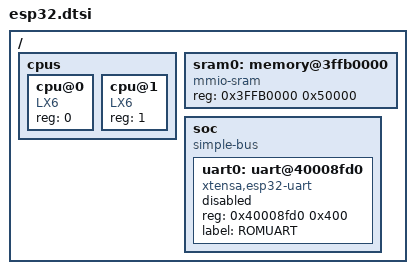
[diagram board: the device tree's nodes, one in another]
/*
 * Copyright (c) 2019 Intel Corporation.
 *
 * SPDX-License-Identifier: Apache-2.0
 */
#include "skeleton.dtsi"

/ {
	cpus {
		#address-cells = <1>;
		#size-cells = <0>;

		cpu@0 {
			device_type = "cpu";
			compatible = "LX6";
			reg = <0>;
		};

		cpu@1 {
			device_type = "cpu";
			compatible = "LX6";
			reg = <1>;
		};

	};

	sram0: memory@3ffb0000 {
		device_type = "memory";
		compatible = "mmio-sram";
		reg = <0x3FFB0000 0x50000>;
	};

	soc {
		#address-cells = <1>;
		#size-cells = <1>;
		compatible = "simple-bus";
		ranges;

		uart0: uart@40008fd0 {
			compatible = "xtensa,esp32-uart";
			reg = <0x40008fd0 0x400>;
			label = "ROMUART";

			status = "disabled";
		};

	};
};
